VERSION ""

NS_ :

BS_:

BU_: DBG DRIVER MOTOR BRIDGE_SENSOR GEO

BO_ 100 DRIVER_HEARTBEAT: 1 DRIVER
 SG_ DRIVER_HEARTBEAT_CMD : 0|8@1+ (1,0) [0|0] "" BRIDGE_SENSOR,MOTOR

BO_ 101 MOTOR_HEARTBEAT: 1 MOTOR
 SG_ MOTOR_HEARTBEAT_CMD : 0|8@1+ (1,0) [0|0] "" DRIVER

BO_ 102 DRIVER_MOTOR_CONTROL: 5 DRIVER
 SG_ DRIVER_MOTOR_CONTROL_SPEED_KPH : 0|12@1+ (0.1,-10) [-10.1|10.1] "kph" MOTOR
 SG_ DRIVER_MOTOR_CONTROL_STEER : 12|16@1+ (0.1,-2) [-2.1|2.1] "degrees" MOTOR

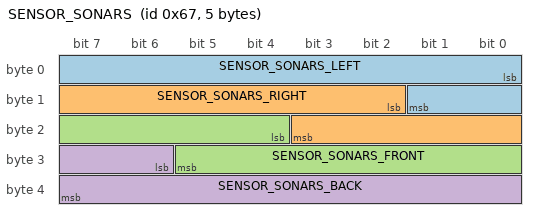
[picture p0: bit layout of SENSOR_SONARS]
BO_ 103 SENSOR_SONARS: 5 BRIDGE_SENSOR
 SG_ SENSOR_SONARS_LEFT : 0|10@1+ (1,0) [0|800] "inch" DRIVER
 SG_ SENSOR_SONARS_RIGHT : 10|10@1+ (1,0) [0|0] "inch" DRIVER
 SG_ SENSOR_SONARS_FRONT : 20|10@1+ (1,0) [0|0] "inch" DRIVER
 SG_ SENSOR_SONARS_BACK : 30|10@1+ (1,0) [0|0] "inch" DRIVER

BO_ 104 GEO_GPS_HEADINGS: 8 GEO
 SG_ GEO_GPS_HEADINGS_CURRENT : 0|32@1+ (0.000001,0) [0|360] "degrees" DRIVER, BRIDGE_SENSOR
 SG_ GEO_GPS_HEADINGS_DESTINATION : 32|32@1+ (0.000001,0) [0|360] "degrees" DRIVER, BRIDGE_SENSOR

BO_ 105 BRIDGE_GPS_HEADINGS: 8 BRIDGE_SENSOR
 SG_ BRIDGE_GPS_HEADINGS_LONGITUDE : 0|32@1- (0.000001, 0) [-360|360] "degrees" GEO
 SG_ BRIDGE_GPS_HEADINGS_LATITUDE : 32|32@1- (0.000001, 0) [-360|360] "degrees" GEO

CM_ BU_ DRIVER "The driver controller driving the car";
CM_ BU_ MOTOR "The motor controller of the car";
CM_ BU_ BRIDGE_SENSOR "The bridge and sensor controller of the car";
CM_ BU_ GEO "The geological controller of the car";
CM_ BO_ 100 "Sync message used to synchronize the controllers";
CM_ SG_ 100 DRIVER_HEARTBEAT_CMD "Heartbeat command from the driver";
CM_ SG_ 101 MOTOR_HEARTBEAT_CMD "Heartbeat command from the motor";

BA_DEF_ "BusType" STRING ;
BA_DEF_ BO_ "GenMsgCycleTime" INT 0 0;
BA_DEF_ SG_ "FieldType" STRING ;

BA_DEF_DEF_ "BusType" "CAN";
BA_DEF_DEF_ "FieldType" "";
BA_DEF_DEF_ "GenMsgCycleTime" 0;

BA_ "GenMsgCycleTime" BO_ 100 1000;
BA_ "GenMsgCycleTime" BO_ 101 1000;
BA_ "GenMsgCycleTime" BO_ 102 100;
BA_ "GenMsgCycleTime" BO_ 103 50;
BA_ "GenMsgCycleTime" BO_ 104 50;
BA_ "GenMsgCycleTime" BO_ 105 100;
BA_ "FieldType" SG_ 100 DRIVER_HEARTBEAT_CMD "DRIVER_HEARTBEAT_CMD";
BA_ "FieldType" SG_ 101 MOTOR_HEARTBEAT_CMD "MOTOR_HEARTBEAT_CMD";

VAL_ 100 DRIVER_HEARTBEAT_CMD 2 "DRIVER_HEARTBEAT_CMD_REBOOT" 1 "DRIVER_HEARTBEAT_CMD_SYNC" 0 "DRIVER_HEARTBEAT_CMD_NOOP" ;
VAL_ 101 MOTOR_HEARTBEAT_CMD 2 "MOTOR_HEARTBEAT_CMD_REBOOT" 1 "MOTOR_HEARTBEAT_CMD_SYNC" 0 "MOTOR_HEARTBEAT_CMD_NOOP" ;
